AUTOSAR XML (schema 00048)
package /MICROSAR/StbM_swc/DataTypes
  20 x impl type:
    StbM_SynchronizedTimeBaseType: range raw 0..65535, implementation-data-type=uint16
    StbM_TimeBaseStatusType:
      compu {mask 1: 0=FALSE (TIMEOUT__FALSE), mask 1: 1=TRUE (TIMEOUT), mask 2: 0=FALSE (Reserved__FALSE), mask 2: 2=TRUE (Reserved), mask 4: 0=FALSE (SYNC_TO_GATEWAY__FALSE), mask 4: 4=TRUE (SYNC_TO_GATEWAY), mask 8: 0=FALSE (GLOBAL_TIME_BASE__FALSE), mask 8: 8=TRUE (GLOBAL_TIME_BASE), mask 16: 0=FALSE (TIMELEAP_FUTURE__FALSE), mask 16: 16=TRUE (TIMELEAP_FUTURE), mask 32: 0=FALSE (TIMELEAP_PAST__FALSE), mask 32: 32=TRUE (TIMELEAP_PAST)}
      range raw 0..63
      implementation-data-type=uint8
    StbM_TimeStampType: category=STRUCTURE
      4 x element, all with category=TYPE_REFERENCE:
        timeBaseStatus: implementation-data-type=StbM_TimeBaseStatusType
        nanoseconds: implementation-data-type=uint32
        seconds: implementation-data-type=uint32
        secondsHi: implementation-data-type=uint16
    StbM_UserDataType: category=STRUCTURE
      4 x element, all with category=TYPE_REFERENCE, implementation-data-type=uint8:
        userDataLength
        userByte{0..2}
    StbM_RateDeviationType: implementation-data-type=sint16
    StbM_SyncRecordTableHeadType: category=STRUCTURE
      element SynchronizedTimeDomain: implementation-data-type=uint8
      element HWfrequency: implementation-data-type=uint32
      element HWprescaler: implementation-data-type=uint32
    StbM_SyncRecordTableBlockType: category=STRUCTURE
      8 x element, all with category=TYPE_REFERENCE:
        GlbSeconds: implementation-data-type=uint32
        GlbNanoSeconds: implementation-data-type=uint32
        TimeBaseStatus: implementation-data-type=StbM_TimeBaseStatusType
        VirtualLocalTimeLow: implementation-data-type=uint32
        RateDeviation: implementation-data-type=sint16
        LocSeconds: implementation-data-type=uint32
        LocNanoSeconds: implementation-data-type=uint32
        PathDelay: implementation-data-type=uint32
    StbM_OffsetRecordTableHeadType: category=STRUCTURE
      element OffsetTimeDomain: implementation-data-type=uint8
    StbM_OffsetRecordTableBlockType: category=STRUCTURE
      element GlbSeconds: implementation-data-type=uint32
      element GlbNanoSeconds: implementation-data-type=uint32
      element TimeBaseStatus: implementation-data-type=StbM_TimeBaseStatusType
    StbM_PortIdType: category=STRUCTURE
      element clockIdentity: implementation-data-type=uint64
      element portNumber: implementation-data-type=uint16
    StbM_TimeStampShortType: category=STRUCTURE
      element nanoseconds: implementation-data-type=uint32
      element seconds: implementation-data-type=uint32
    StbM_VirtualLocalTimeType: category=STRUCTURE
      element nanosecondsLo: implementation-data-type=uint32
      element nanosecondsHi: implementation-data-type=uint32
    StbM_EthTimeMasterMeasurementType: category=STRUCTURE
      5 x element, all with category=TYPE_REFERENCE:
        sequenceId: implementation-data-type=uint16
        sourcePortId: implementation-data-type=StbM_PortIdType
        syncEgressTimestamp: implementation-data-type=StbM_VirtualLocalTimeType
        preciseOriginTimestamp: implementation-data-type=StbM_TimeStampShortType
        correctionField: implementation-data-type=sint64
    StbM_EthTimeSlaveMeasurementType: category=STRUCTURE
      8 x element, all with category=TYPE_REFERENCE:
        sequenceId: implementation-data-type=uint16
        sourcePortId: implementation-data-type=StbM_PortIdType
        syncIngressTimestamp: implementation-data-type=StbM_VirtualLocalTimeType
        preciseOriginTimestamp: implementation-data-type=StbM_TimeStampShortType
        correctionField: implementation-data-type=sint64
        pDelay: implementation-data-type=uint32
        referenceLocalTimestamp: implementation-data-type=StbM_VirtualLocalTimeType
        referenceGlobalTimestamp: implementation-data-type=StbM_TimeStampShortType
    StbM_PdelayInitiatorMeasurementType: category=STRUCTURE
      10 x element, all with category=TYPE_REFERENCE:
        sequenceId: implementation-data-type=uint16
        requestPortId: implementation-data-type=StbM_PortIdType
        responsePortId: implementation-data-type=StbM_PortIdType
        requestOriginTimestamp: implementation-data-type=StbM_VirtualLocalTimeType
        responseReceiptTimestamp: implementation-data-type=StbM_VirtualLocalTimeType
        requestReceiptTimestamp: implementation-data-type=StbM_TimeStampShortType
        responseOriginTimestamp: implementation-data-type=StbM_TimeStampShortType
        referenceLocalTimestamp: implementation-data-type=StbM_VirtualLocalTimeType
        referenceGlobalTimestamp: implementation-data-type=StbM_TimeStampShortType
        pdelay: implementation-data-type=uint32
    StbM_PdelayResponderMeasurementType: category=STRUCTURE
      7 x element, all with category=TYPE_REFERENCE:
        sequenceId: implementation-data-type=uint16
        requestPortId: implementation-data-type=StbM_PortIdType
        responsePortId: implementation-data-type=StbM_PortIdType
        requestReceiptTimestamp: implementation-data-type=StbM_VirtualLocalTimeType
        responseOriginTimestamp: implementation-data-type=StbM_VirtualLocalTimeType
        referenceLocalTimestamp: implementation-data-type=StbM_VirtualLocalTimeType
        referenceGlobalTimestamp: implementation-data-type=StbM_TimeStampShortType
    StbM_TimeDiffType: range raw -2147483648..2147483647, implementation-data-type=sint32
    StbM_TimeBaseNotificationType:
      compu {mask 1: 0=FALSE (EV_GLOBAL_TIME__FALSE), mask 1: 1=TRUE (EV_GLOBAL_TIME), mask 2: 0=FALSE (EV_TIMEOUT_OCCURRED__FALSE), mask 2: 2=TRUE (EV_TIMEOUT_OCCURRED), mask 4: 0=FALSE (EV_TIMEOUT_REMOVED__FALSE), mask 4: 4=TRUE (EV_TIMEOUT_REMOVED), mask 8: 0=FALSE (EV_TIMELEAP_FUTURE__FALSE), mask 8: 8=TRUE (EV_TIMELEAP_FUTURE), mask 16: 0=FALSE (EV_TIMELEAP_FUTURE_REMOVED__FALSE), mask 16: 16=TRUE (EV_TIMELEAP_FUTURE_REMOVED), mask 32: 0=FALSE (EV_TIMELEAP_PAST__FALSE), mask 32: 32=TRUE (EV_TIMELEAP_PAST), mask 64: 0=FALSE (EV_TIMELEAP_PAST_REMOVED__FALSE), mask 64: 64=TRUE (EV_TIMELEAP_PAST_REMOVED), mask 128: 0=FALSE (EV_SYNC_TO_SUBDOMAIN__FALSE), mask 128: 128=TRUE (EV_SYNC_TO_SUBDOMAIN), mask 256: 0=FALSE (EV_SYNC_TO_GLOBAL_MASTER__FALSE), mask 256: 256=TRUE (EV_SYNC_TO_GLOBAL_MASTER), mask 512: 0=FALSE (EV_RESYNC__FALSE), mask 512: 512=TRUE (EV_RESYNC), mask 1024: 0=FALSE (EV_RATECORRECTION__FALSE), mask 1024: 1024=TRUE (EV_RATECORRECTION)}
      range raw 0..4294967295
      implementation-data-type=uint32
    StbM_CustomerIdType: range raw 0..65535, implementation-data-type=uint16
    StbM_MasterConfigType: compu {0=STBM_SYSTEM_WIDE_MASTER_DISABLED, 1=STBM_SYSTEM_WIDE_MASTER_ENABLED}, range raw 0..255, implementation-data-type=uint8  # The value of this type is STBM_SYSTEM_WIDE_MASTER_ENABLED if and only if an ECU is configured as system wide master for a given timebase and STBM_SYSTEM_WIDE_MASTER_DISABLED otherwise.
package /MICROSAR/StbM_swc/Interfaces
  client server interface GlobalTime_Slave_StbMSynchronizedTimeBase_MAIN0: is-service=true, service-kind=SYNC-BASE-TIME-MANAGER
    4 x operation, all with possible-error=[GlobalTime_Slave_StbMSynchronizedTimeBase_MAIN0/E_OK, GlobalTime_Slave_StbMSynchronizedTimeBase_MAIN0/E_NOT_OK]:
      GetCurrentTime
        arg timeStampPtr: type=StbM_TimeStampType, direction=OUT
        arg userDataPtr: type=StbM_UserDataType, direction=OUT
      GetRateDeviation
        arg rateDeviation: type=StbM_RateDeviationType, direction=OUT
      GetTimeLeap
        arg timeJump: type=StbM_TimeDiffType, direction=OUT
      GetTimeBaseStatus
        arg syncTimeBaseStatus: type=StbM_TimeBaseStatusType, direction=OUT
        arg offsetTimeBaseStatus: type=StbM_TimeBaseStatusType, direction=OUT
    error E_OK: error-code=0
    error E_NOT_OK: error-code=1
  client server interface GlobalTime_Slave_StbMSynchronizedTimeBase_MAIN6: is-service=true, service-kind=SYNC-BASE-TIME-MANAGER
    4 x operation, all with possible-error=[GlobalTime_Slave_StbMSynchronizedTimeBase_MAIN6/E_OK, GlobalTime_Slave_StbMSynchronizedTimeBase_MAIN6/E_NOT_OK]:
      GetCurrentTime
        arg timeStampPtr: type=StbM_TimeStampType, direction=OUT
        arg userDataPtr: type=StbM_UserDataType, direction=OUT
      GetRateDeviation
        arg rateDeviation: type=StbM_RateDeviationType, direction=OUT
      GetTimeLeap
        arg timeJump: type=StbM_TimeDiffType, direction=OUT
      GetTimeBaseStatus
        arg syncTimeBaseStatus: type=StbM_TimeBaseStatusType, direction=OUT
        arg offsetTimeBaseStatus: type=StbM_TimeBaseStatusType, direction=OUT
    error E_OK: error-code=0
    error E_NOT_OK: error-code=1
  client server interface GlobalTime_Master_StbMSynchronizedTimeBase_MAIN6: is-service=true, service-kind=SYNC-BASE-TIME-MANAGER
    5 x operation, all with possible-error=[GlobalTime_Master_StbMSynchronizedTimeBase_MAIN6/E_OK, GlobalTime_Master_StbMSynchronizedTimeBase_MAIN6/E_NOT_OK]:
      SetGlobalTime
        arg timeStampPtr: type=StbM_TimeStampType, direction=IN
        arg userDataPtr: type=StbM_UserDataType, direction=IN
      SetUserData
        arg userDataPtr: type=StbM_UserDataType, direction=IN
      SetRateCorrection
        arg rateDeviation: type=StbM_RateDeviationType, direction=IN
      TriggerTimeTransmission
      UpdateGlobalTime
        arg timeStamp: type=StbM_TimeStampType, direction=IN
        arg userData: type=StbM_UserDataType, direction=IN
    error E_OK: error-code=0
    error E_NOT_OK: error-code=1
package /MICROSAR/StbM_swc/ComponentTypes
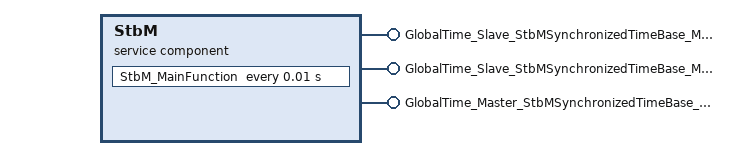
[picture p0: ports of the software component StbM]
  service sw component type StbM: category=SERVICE_COMPONENT
    provide port GlobalTime_Slave_StbMSynchronizedTimeBase_MAIN0: provided-interface=GlobalTime_Slave_StbMSynchronizedTimeBase_MAIN0
    provide port GlobalTime_Slave_StbMSynchronizedTimeBase_MAIN6: provided-interface=GlobalTime_Slave_StbMSynchronizedTimeBase_MAIN6
    provide port GlobalTime_Master_StbMSynchronizedTimeBase_MAIN6: provided-interface=GlobalTime_Master_StbMSynchronizedTimeBase_MAIN6
    behavior StbMInternalBehavior: handle-termination-and-restart=NO-SUPPORT, included-data-type-set=data-type=[StbM_SynchronizedTimeBaseType, StbM_TimeBaseStatusType, StbM_TimeStampType, StbM_UserDataType, StbM_RateDeviationType, StbM_SyncRecordTableHeadType, StbM_SyncRecordTableBlockType, StbM_OffsetRecordTableHeadType, StbM_OffsetRecordTableBlockType, StbM_PortIdType, StbM_TimeStampShortType, StbM_VirtualLocalTimeType, StbM_EthTimeMasterMeasurementType, StbM_EthTimeSlaveMeasurementType, StbM_PdelayInitiatorMeasurementType, StbM_PdelayResponderMeasurementType, StbM_TimeDiffType, StbM_TimeBaseNotificationType, StbM_CustomerIdType, StbM_MasterConfigType]
      timing event Timer_StbM_MainFunction: start-on-event=StbM_MainFunction, period=0.01
      13 x operation invoked event:
        OpEventGetCurrentTime_GetCurrentTime_GlobalTime_Slave_StbMSynchronizedTimeBase_MAIN0: start-on-event=GetCurrentTime, operation=GlobalTime_Slave_StbMSynchronizedTimeBase_MAIN0.GetCurrentTime
        OpEventGetCurrentTime_GetCurrentTime_GlobalTime_Slave_StbMSynchronizedTimeBase_MAIN6: start-on-event=GetCurrentTime, operation=GlobalTime_Slave_StbMSynchronizedTimeBase_MAIN6.GetCurrentTime
        OpEventGetRateDeviation_GetRateDeviation_GlobalTime_Slave_StbMSynchronizedTimeBase_MAIN0: start-on-event=GetRateDeviation, operation=GlobalTime_Slave_StbMSynchronizedTimeBase_MAIN0.GetRateDeviation
        OpEventGetRateDeviation_GetRateDeviation_GlobalTime_Slave_StbMSynchronizedTimeBase_MAIN6: start-on-event=GetRateDeviation, operation=GlobalTime_Slave_StbMSynchronizedTimeBase_MAIN6.GetRateDeviation
        OpEventGetTimeLeap_GetTimeLeap_GlobalTime_Slave_StbMSynchronizedTimeBase_MAIN0: start-on-event=GetTimeLeap, operation=GlobalTime_Slave_StbMSynchronizedTimeBase_MAIN0.GetTimeLeap
        OpEventGetTimeLeap_GetTimeLeap_GlobalTime_Slave_StbMSynchronizedTimeBase_MAIN6: start-on-event=GetTimeLeap, operation=GlobalTime_Slave_StbMSynchronizedTimeBase_MAIN6.GetTimeLeap
        OpEventGetTimeBaseStatus_GetTimeBaseStatus_GlobalTime_Slave_StbMSynchronizedTimeBase_MAIN0: start-on-event=GetTimeBaseStatus, operation=GlobalTime_Slave_StbMSynchronizedTimeBase_MAIN0.GetTimeBaseStatus
        OpEventGetTimeBaseStatus_GetTimeBaseStatus_GlobalTime_Slave_StbMSynchronizedTimeBase_MAIN6: start-on-event=GetTimeBaseStatus, operation=GlobalTime_Slave_StbMSynchronizedTimeBase_MAIN6.GetTimeBaseStatus
        OpEventSetGlobalTime_SetGlobalTime_GlobalTime_Master_StbMSynchronizedTimeBase_MAIN6: start-on-event=SetGlobalTime, operation=GlobalTime_Master_StbMSynchronizedTimeBase_MAIN6.SetGlobalTime
        OpEventSetUserData_SetUserData_GlobalTime_Master_StbMSynchronizedTimeBase_MAIN6: start-on-event=SetUserData, operation=GlobalTime_Master_StbMSynchronizedTimeBase_MAIN6.SetUserData
        OpEventSetRateCorrection_SetRateCorrection_GlobalTime_Master_StbMSynchronizedTimeBase_MAIN6: start-on-event=SetRateCorrection, operation=GlobalTime_Master_StbMSynchronizedTimeBase_MAIN6.SetRateCorrection
        OpEventTriggerTimeTransmission_TriggerTimeTransmission_GlobalTime_Master_StbMSynchronizedTimeBase_MAIN6: start-on-event=TriggerTimeTransmission, operation=GlobalTime_Master_StbMSynchronizedTimeBase_MAIN6.TriggerTimeTransmission
        OpEventUpdateGlobalTime_UpdateGlobalTime_GlobalTime_Master_StbMSynchronizedTimeBase_MAIN6: start-on-event=UpdateGlobalTime, operation=GlobalTime_Master_StbMSynchronizedTimeBase_MAIN6.UpdateGlobalTime
      port-api-options:
        {enable-take-address=true, indirect-api=false, port-defined-argument-value{value=0, value-type=StbM_SynchronizedTimeBaseType}, port=GlobalTime_Slave_StbMSynchronizedTimeBase_MAIN0}
        {enable-take-address=true, indirect-api=false, port-defined-argument-value{value=1, value-type=StbM_SynchronizedTimeBaseType}, port=GlobalTime_Slave_StbMSynchronizedTimeBase_MAIN6}
        {enable-take-address=true, indirect-api=false, port-defined-argument-value{value=1, value-type=StbM_SynchronizedTimeBaseType}, port=GlobalTime_Master_StbMSynchronizedTimeBase_MAIN6}
      10 x runnable:
        StbM_MainFunction
        GetCurrentTime: can-be-invoked-concurrently=true, symbol=StbM_GetCurrentTime
        GetRateDeviation: can-be-invoked-concurrently=true, symbol=StbM_GetRateDeviation
        GetTimeLeap: can-be-invoked-concurrently=true, symbol=StbM_GetTimeLeap
        GetTimeBaseStatus: can-be-invoked-concurrently=true, symbol=StbM_GetTimeBaseStatus
        SetGlobalTime: can-be-invoked-concurrently=true, symbol=StbM_SetGlobalTime
        SetUserData: can-be-invoked-concurrently=true, symbol=StbM_SetUserData
        SetRateCorrection: can-be-invoked-concurrently=true, symbol=StbM_SetRateCorrection
        TriggerTimeTransmission: can-be-invoked-concurrently=true, symbol=StbM_TriggerTimeTransmission
        UpdateGlobalTime: can-be-invoked-concurrently=true, symbol=StbM_UpdateGlobalTime
  swc implementation StbMImplementation: programming-language=C, behavior=StbMInternalBehavior
